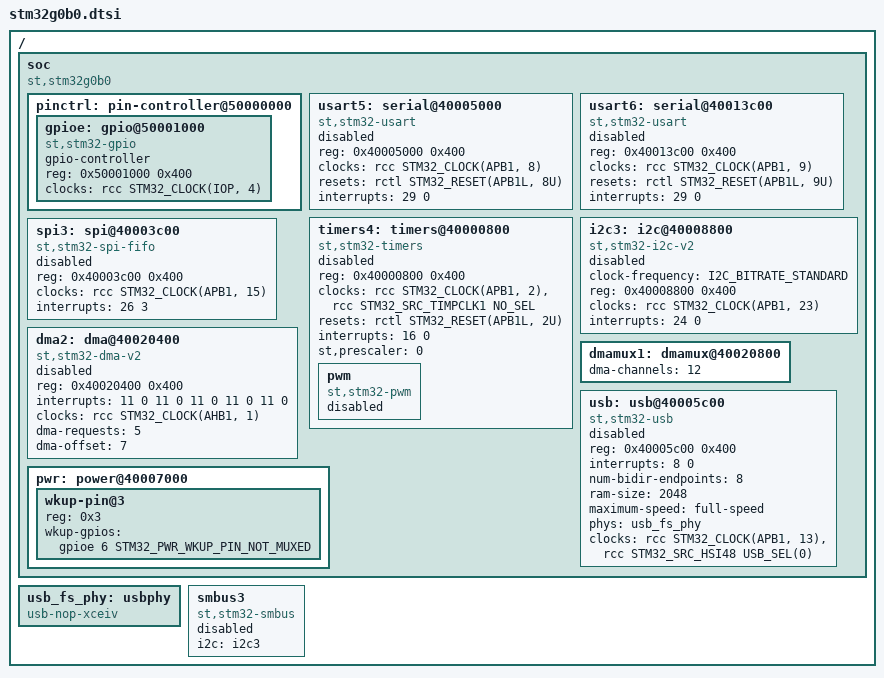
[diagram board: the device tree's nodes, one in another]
/*
 * Copyright (c) 2020 Thomas Stranger
 *
 * SPDX-License-Identifier: Apache-2.0
 */

#include <st/g0/stm32g070.dtsi>

/ {
	soc {
		compatible = "st,stm32g0b0", "st,stm32g0", "simple-bus";

		pinctrl: pin-controller@50000000 {
			gpioe: gpio@50001000 {
				compatible = "st,stm32-gpio";
				gpio-controller;
				#gpio-cells = <2>;
				reg = <0x50001000 0x400>;
				clocks = <&rcc STM32_CLOCK(IOP, 4)>;
			};
		};

		usart5: serial@40005000 {
			compatible = "st,stm32-usart", "st,stm32-uart";
			reg = <0x40005000 0x400>;
			clocks = <&rcc STM32_CLOCK(APB1, 8)>;
			resets = <&rctl STM32_RESET(APB1L, 8U)>;
			interrupts = <29 0>;
			status = "disabled";
		};

		usart6: serial@40013c00 {
			compatible = "st,stm32-usart", "st,stm32-uart";
			reg = <0x40013c00 0x400>;
			clocks = <&rcc STM32_CLOCK(APB1, 9)>;
			resets = <&rctl STM32_RESET(APB1L, 9U)>;
			interrupts = <29 0>;
			status = "disabled";
		};

		timers4: timers@40000800 {
			compatible = "st,stm32-timers";
			reg = <0x40000800 0x400>;
			clocks = <&rcc STM32_CLOCK(APB1, 2)>,
				 <&rcc STM32_SRC_TIMPCLK1 NO_SEL>;
			resets = <&rctl STM32_RESET(APB1L, 2U)>;
			interrupts = <16 0>;
			interrupt-names = "global";
			st,prescaler = <0>;
			status = "disabled";

			pwm {
				compatible = "st,stm32-pwm";
				status = "disabled";
				#pwm-cells = <3>;
			};
		};

		i2c3: i2c@40008800 {
			compatible = "st,stm32-i2c-v2";
			clock-frequency = <I2C_BITRATE_STANDARD>;
			#address-cells = <1>;
			#size-cells = <0>;
			reg = <0x40008800 0x400>;
			clocks = <&rcc STM32_CLOCK(APB1, 23)>;
			interrupts = <24 0>;
			interrupt-names = "combined";
			status = "disabled";
		};

		spi3: spi@40003c00 {
			compatible = "st,stm32-spi-fifo", "st,stm32-spi";
			#address-cells = <1>;
			#size-cells = <0>;
			reg = <0x40003c00 0x400>;
			clocks = <&rcc STM32_CLOCK(APB1, 15)>;
			interrupts = <26 3>;
			status = "disabled";
		};

		dma2: dma@40020400 {
			compatible = "st,stm32-dma-v2";
			#dma-cells = <3>;
			reg = <0x40020400 0x400>;
			interrupts = <11 0 11 0 11 0 11 0 11 0>;
			clocks = <&rcc STM32_CLOCK(AHB1, 1)>;
			dma-requests = <5>;
			dma-offset = <7>;
			status = "disabled";
		};

		dmamux1: dmamux@40020800 {
			dma-channels = <12>;
		};

		usb: usb@40005c00 {
			compatible = "st,stm32-usb";
			reg = <0x40005c00 0x400>;
			interrupts = <8 0>;
			interrupt-names = "usb";
			num-bidir-endpoints = <8>;
			ram-size = <2048>;
			maximum-speed = "full-speed";
			phys = <&usb_fs_phy>;
			clocks = <&rcc STM32_CLOCK(APB1, 13)>,
				 <&rcc STM32_SRC_HSI48 USB_SEL(0)>;
			status = "disabled";
		};

		pwr: power@40007000 {
			wkup-pin@3 {
				reg = <0x3>;
				wkup-gpios = <&gpioe 6 STM32_PWR_WKUP_PIN_NOT_MUXED>;
			};
		};
	};

	usb_fs_phy: usbphy {
		compatible = "usb-nop-xceiv";
		#phy-cells = <0>;
	};

	smbus3: smbus3 {
		compatible = "st,stm32-smbus";
		#address-cells = <1>;
		#size-cells = <0>;
		i2c = <&i2c3>;
		status = "disabled";
	};
};
